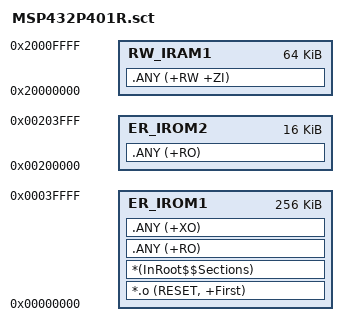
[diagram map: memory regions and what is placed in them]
LR_IROM1 0x00000000 0x00040000 {
  ER_IROM1 0x00000000 0x00040000 {
   *.o (RESET, +First)
   *(InRoot$$Sections)
   .ANY (+RO)
   .ANY (+XO)
  }
  RW_IRAM1 0x20000000 0x00010000 {
   .ANY (+RW +ZI)
  }
}

LR_IROM2 0x00200000 0x00004000 {
  ER_IROM2 0x00200000 0x00004000 {
   .ANY (+RO)
  }
}
